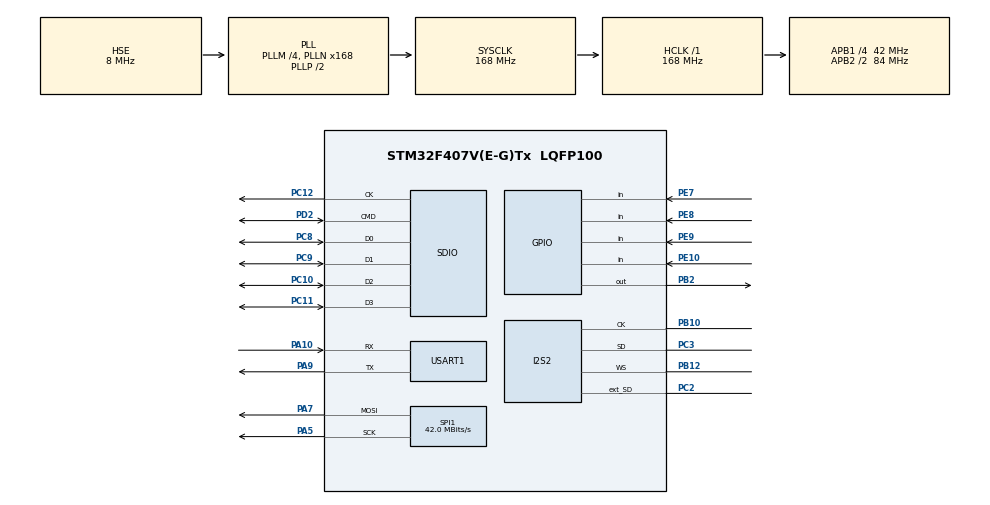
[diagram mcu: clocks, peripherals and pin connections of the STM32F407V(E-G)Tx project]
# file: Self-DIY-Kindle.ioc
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Dma.Request0=SDIO_RX
Dma.Request1=SDIO_TX
Dma.Request2=SPI1_TX
Dma.SDIO_RX.0.Direction=DMA_PERIPH_TO_MEMORY
Dma.SDIO_RX.0.FIFOMode=DMA_FIFOMODE_ENABLE
Dma.SDIO_RX.0.FIFOThreshold=DMA_FIFO_THRESHOLD_FULL
Dma.SDIO_RX.0.Instance=DMA2_Stream3
Dma.SDIO_RX.0.MemBurst=DMA_MBURST_INC4
Dma.SDIO_RX.0.MemDataAlignment=DMA_MDATAALIGN_WORD
Dma.SDIO_RX.0.MemInc=DMA_MINC_ENABLE
Dma.SDIO_RX.0.Mode=DMA_PFCTRL
Dma.SDIO_RX.0.PeriphBurst=DMA_PBURST_INC4
Dma.SDIO_RX.0.PeriphDataAlignment=DMA_PDATAALIGN_WORD
Dma.SDIO_RX.0.PeriphInc=DMA_PINC_DISABLE
Dma.SDIO_RX.0.Priority=DMA_PRIORITY_LOW
Dma.SDIO_TX.1.Direction=DMA_MEMORY_TO_PERIPH
Dma.SDIO_TX.1.FIFOMode=DMA_FIFOMODE_ENABLE
Dma.SDIO_TX.1.FIFOThreshold=DMA_FIFO_THRESHOLD_FULL
Dma.SDIO_TX.1.Instance=DMA2_Stream6
Dma.SDIO_TX.1.MemBurst=DMA_MBURST_INC4
Dma.SDIO_TX.1.MemDataAlignment=DMA_MDATAALIGN_WORD
Dma.SDIO_TX.1.MemInc=DMA_MINC_ENABLE
Dma.SDIO_TX.1.Mode=DMA_PFCTRL
Dma.SDIO_TX.1.PeriphBurst=DMA_PBURST_INC4
Dma.SDIO_TX.1.PeriphDataAlignment=DMA_PDATAALIGN_WORD
Dma.SDIO_TX.1.PeriphInc=DMA_PINC_DISABLE
Dma.SDIO_TX.1.Priority=DMA_PRIORITY_LOW
Dma.SPI1_TX.2.Direction=DMA_MEMORY_TO_PERIPH
Dma.SPI1_TX.2.FIFOMode=DMA_FIFOMODE_DISABLE
Dma.SPI1_TX.2.Instance=DMA2_Stream5
Dma.SPI1_TX.2.MemDataAlignment=DMA_MDATAALIGN_BYTE
Dma.SPI1_TX.2.MemInc=DMA_MINC_ENABLE
Dma.SPI1_TX.2.Mode=DMA_NORMAL
Dma.SPI1_TX.2.PeriphDataAlignment=DMA_PDATAALIGN_BYTE
Dma.SPI1_TX.2.PeriphInc=DMA_PINC_DISABLE
Dma.SPI1_TX.2.Priority=DMA_PRIORITY_LOW
FREERTOS.INCLUDE_vTaskDelayUntil=1
FREERTOS.Tasks01=defaultTask,-3,128,StartDefaultTask,Default,NULL,Dynamic,NULL,NULL;InputTask,1,128,StartInputTask,As external,NULL,Dynamic,NULL,NULL;MusicTask,0,128,StartMusicTask,As external,NULL,Dynamic,NULL,NULL;NetTask,-3,128,StartNetTask,As external,NULL,Dynamic,NULL,NULL;ProcessTask,-1,512,StartProcessTask,As external,NULL,Dynamic,NULL,NULL;UITask,0,1024,StartUITask,As external,NULL,Dynamic,NULL,NULL;TestTask,-3,512,StartTestTask,As external,NULL,Dynamic,NULL,NULL
FREERTOS.configCHECK_FOR_STACK_OVERFLOW=2
FREERTOS.configGENERATE_RUN_TIME_STATS=0
FREERTOS.configRECORD_STACK_HIGH_ADDRESS=1
I2S2.AudioFreq=I2S_AUDIOFREQ_96K
I2S2.DataFormat=I2S_DATAFORMAT_32B
I2S2.ErrorAudioFreq=0.8 %
I2S2.FullDuplexMode=I2S_FULLDUPLEXMODE_ENABLE
I2S2.Instance=SPI$Index
I2S2.RealAudioFreq=96.774 KHz
I2S2.VirtualMode=I2S_MODE_MASTER
Mcu.Family=STM32F4
Mcu.Name=STM32F407V(E-G)Tx
Mcu.Package=LQFP100
NVIC.DMA2_Stream3_IRQn=true\:5\:0\:false\:false\:true\:true\:false\:true\:true
NVIC.DMA2_Stream5_IRQn=true\:5\:0\:false\:false\:true\:true\:false\:true\:true
NVIC.DMA2_Stream6_IRQn=true\:5\:0\:false\:false\:true\:true\:false\:true\:true
NVIC.PriorityGroup=NVIC_PRIORITYGROUP_4
NVIC.TIM7_IRQn=true\:15\:0\:false\:false\:true\:false\:false\:true\:true
NVIC.TimeBase=TIM7_IRQn
NVIC.TimeBaseIP=TIM7
NVIC.USART1_IRQn=true\:5\:0\:false\:false\:true\:true\:true\:true\:true
PA10.Mode=Asynchronous
PA10.Signal=USART1_RX
PA13.Mode=Serial_Wire
PA13.Signal=SYS_JTMS-SWDIO
PA14.Mode=Serial_Wire
PA14.Signal=SYS_JTCK-SWCLK
PA5.Mode=TX_Only_Simplex_Unidirect_Master
PA5.Signal=SPI1_SCK
PA7.Mode=TX_Only_Simplex_Unidirect_Master
PA7.Signal=SPI1_MOSI
PA9.Mode=Asynchronous
PA9.Signal=USART1_TX
PB10.Mode=Full_Duplex_Master
PB10.Signal=I2S2_CK
PB12.Mode=Full_Duplex_Master
PB12.Signal=I2S2_WS
PB2.Signal=GPIO_Output
PC10.Mode=SD_4_bits_Wide_bus
PC10.Signal=SDIO_D2
PC11.Mode=SD_4_bits_Wide_bus
PC11.Signal=SDIO_D3
PC12.Mode=SD_4_bits_Wide_bus
PC12.Signal=SDIO_CK
PC14-OSC32_IN.Mode=LSE-External-Oscillator
PC14-OSC32_IN.Signal=RCC_OSC32_IN
PC15-OSC32_OUT.Mode=LSE-External-Oscillator
PC15-OSC32_OUT.Signal=RCC_OSC32_OUT
PC2.Mode=Full_Duplex_Master
PC2.Signal=I2S2_ext_SD
PC3.Mode=Full_Duplex_Master
PC3.Signal=I2S2_SD
PC8.Mode=SD_4_bits_Wide_bus
PC8.Signal=SDIO_D0
PC9.Mode=SD_4_bits_Wide_bus
PC9.Signal=SDIO_D1
PD2.Mode=SD_4_bits_Wide_bus
PD2.Signal=SDIO_CMD
PE10.Signal=GPIO_Input
PE7.Signal=GPIO_Input
PE8.Signal=GPIO_Input
PE9.Signal=GPIO_Input
PH0-OSC_IN.Mode=HSE-External-Oscillator
PH0-OSC_IN.Signal=RCC_OSC_IN
PH1-OSC_OUT.Mode=HSE-External-Oscillator
PH1-OSC_OUT.Signal=RCC_OSC_OUT
ProjectManager.HeapSize=0x200
ProjectManager.StackSize=0x400
ProjectManager.TargetToolchain=Makefile
RCC.48MHZClocksFreq_Value=42000000
RCC.AHBFreq_Value=168000000
RCC.APB1CLKDivider=RCC_HCLK_DIV4
RCC.APB1Freq_Value=42000000
RCC.APB1TimFreq_Value=84000000
RCC.APB2CLKDivider=RCC_HCLK_DIV2
RCC.APB2Freq_Value=84000000
RCC.APB2TimFreq_Value=168000000
RCC.CortexFreq_Value=168000000
RCC.HCLKFreq_Value=168000000
RCC.HSE_VALUE=8000000
RCC.HSI_VALUE=16000000
RCC.PLLM=4
RCC.PLLN=168
RCC.PLLQ=8
RCC.PLLSourceVirtual=RCC_PLLSOURCE_HSE
RCC.SYSCLKFreq_VALUE=168000000
RCC.SYSCLKSource=RCC_SYSCLKSOURCE_PLLCLK
RCC.VCOOutputFreq_Value=336000000
SPI1.CalculateBaudRate=42.0 MBits/s
SPI1.Direction=SPI_DIRECTION_2LINES
SPI1.Mode=SPI_MODE_MASTER
SPI1.VirtualType=VM_MASTER
USART1.VirtualMode=VM_ASYNC
VP_FREERTOS_VS_CMSIS_V1.Mode=CMSIS_V1
VP_SYS_VS_tim7.Mode=TIM7
board=custom

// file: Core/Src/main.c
/* USER CODE BEGIN Header */
/**
 ******************************************************************************
 * @file           : main.c
 * @brief          : Main program body
 ******************************************************************************
 * @attention
 *
 * Copyright (c) 2026 STMicroelectronics.
 * All rights reserved.
 *
 * This software is licensed under terms that can be found in the LICENSE file
 * in the root directory of this software component.
 * If no LICENSE file comes with this software, it is provided AS-IS.
 *
 ******************************************************************************
 */
/* USER CODE END Header */
#include "main.h"
#include "cmsis_os.h"
#include "dma.h"
#include "i2s.h"
#include "sdio.h"
#include "spi.h"
#include "usart.h"
#include "gpio.h"

/* USER CODE BEGIN Includes */
#include "bsp_config.h"
#include "bsp_sys.h"
#include "mid_config.h"
#include "srv_config.h"

/* USER CODE END Includes */

void SystemClock_Config(void);
void MX_FREERTOS_Init(void);

int main(void)
{

  /* MCU Configuration--------------------------------------------------------*/

  /* Reset of all peripherals, Initializes the Flash interface and the Systick. */
  HAL_Init();

  /* Configure the system clock */
  SystemClock_Config();

  /* Initialize all configured peripherals */
  MX_GPIO_Init();
  MX_DMA_Init();
  MX_SDIO_SD_Init();
  MX_SPI1_Init();
  MX_USART1_UART_Init();
  MX_I2S2_Init();
  /* USER CODE BEGIN 2 */
    /* 初始化 RTT 调试支持 */
    rtt_init();
    sys_chip_init();
    bsp_init_hardware();
    mid_init_modules();

    service_init();

    /* start testing signal */
    gpio_write(&usr_led, GPIO_Level_High);
  /* USER CODE END 2 */

  /* Call init function for freertos objects (in cmsis_os2.c) */
  MX_FREERTOS_Init();

  /* Start scheduler */
  osKernelStart();

  /* We should never get here as control is now taken by the scheduler */

  /* Infinite loop */
    while (1) {

    }
}

void SystemClock_Config(void)
{
  RCC_OscInitTypeDef RCC_OscInitStruct = {0};
  RCC_ClkInitTypeDef RCC_ClkInitStruct = {0};

  /** Configure the main internal regulator output voltage
  */
  __HAL_RCC_PWR_CLK_ENABLE();
  __HAL_PWR_VOLTAGESCALING_CONFIG(PWR_REGULATOR_VOLTAGE_SCALE1);

  /** Initializes the RCC Oscillators according to the specified parameters
  * in the RCC_OscInitTypeDef structure.
  */
  RCC_OscInitStruct.OscillatorType = RCC_OSCILLATORTYPE_HSE;
  RCC_OscInitStruct.HSEState = RCC_HSE_ON;
  RCC_OscInitStruct.PLL.PLLState = RCC_PLL_ON;
  RCC_OscInitStruct.PLL.PLLSource = RCC_PLLSOURCE_HSE;
  RCC_OscInitStruct.PLL.PLLM = 4;
  RCC_OscInitStruct.PLL.PLLN = 168;
  RCC_OscInitStruct.PLL.PLLP = RCC_PLLP_DIV2;
  RCC_OscInitStruct.PLL.PLLQ = 8;
  if (HAL_RCC_OscConfig(&RCC_OscInitStruct) != HAL_OK)
  {
    Error_Handler();
  }

  /** Initializes the CPU, AHB and APB buses clocks
  */
  RCC_ClkInitStruct.ClockType = RCC_CLOCKTYPE_HCLK|RCC_CLOCKTYPE_SYSCLK
                              |RCC_CLOCKTYPE_PCLK1|RCC_CLOCKTYPE_PCLK2;
  RCC_ClkInitStruct.SYSCLKSource = RCC_SYSCLKSOURCE_PLLCLK;
  RCC_ClkInitStruct.AHBCLKDivider = RCC_SYSCLK_DIV1;
  RCC_ClkInitStruct.APB1CLKDivider = RCC_HCLK_DIV4;
  RCC_ClkInitStruct.APB2CLKDivider = RCC_HCLK_DIV2;

  if (HAL_RCC_ClockConfig(&RCC_ClkInitStruct, FLASH_LATENCY_5) != HAL_OK)
  {
    Error_Handler();
  }
}

void HAL_TIM_PeriodElapsedCallback(TIM_HandleTypeDef *htim)
{
  if (htim->Instance == TIM7)
  {
    HAL_IncTick();
  }
}

void Error_Handler(void)
{
  /* USER CODE BEGIN Error_Handler_Debug */
    /* User can add his own implementation to report the HAL error return state */
    __disable_irq();
    gpio_write(&usr_led, GPIO_Level_Low);
    while (1) {
    }
  /* USER CODE END Error_Handler_Debug */
}

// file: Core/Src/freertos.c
/* USER CODE BEGIN Header */
/**
  ******************************************************************************
  * File Name          : freertos.c
  * Description        : Code for freertos applications
  ******************************************************************************
  * @attention
  *
  * Copyright (c) 2026 STMicroelectronics.
  * All rights reserved.
  *
  * This software is licensed under terms that can be found in the LICENSE file
  * in the root directory of this software component.
  * If no LICENSE file comes with this software, it is provided AS-IS.
  *
  ******************************************************************************
  */
/* USER CODE END Header */

#include "FreeRTOS.h"
#include "task.h"
#include "main.h"
#include "cmsis_os.h"

osThreadId defaultTaskHandle;
osThreadId InputTaskHandle;
osThreadId MusicTaskHandle;
osThreadId NetTaskHandle;
osThreadId ProcessTaskHandle;
osThreadId UITaskHandle;
osThreadId TestTaskHandle;

void StartDefaultTask(void const * argument);
extern void StartInputTask(void const * argument);
extern void StartMusicTask(void const * argument);
extern void StartNetTask(void const * argument);
extern void StartProcessTask(void const * argument);
extern void StartUITask(void const * argument);
extern void StartTestTask(void const * argument);

void MX_FREERTOS_Init(void); /* (MISRA C 2004 rule 8.1) */

/* GetIdleTaskMemory prototype (linked to static allocation support) */
void vApplicationGetIdleTaskMemory( StaticTask_t **ppxIdleTaskTCBBuffer, StackType_t **ppxIdleTaskStackBuffer, uint32_t *pulIdleTaskStackSize );

/* Hook prototypes */
void vApplicationStackOverflowHook(xTaskHandle xTask, signed char *pcTaskName);

/* USER CODE BEGIN 4 */
__weak void vApplicationStackOverflowHook(xTaskHandle xTask, signed char *pcTaskName)
{
   /* Run time stack overflow checking is performed if
   configCHECK_FOR_STACK_OVERFLOW is defined to 1 or 2. This hook function is
   called if a stack overflow is detected. */
}
/* USER CODE END 4 */

/* USER CODE BEGIN GET_IDLE_TASK_MEMORY */
static StaticTask_t xIdleTaskTCBBuffer;
static StackType_t xIdleStack[configMINIMAL_STACK_SIZE];

void vApplicationGetIdleTaskMemory( StaticTask_t **ppxIdleTaskTCBBuffer, StackType_t **ppxIdleTaskStackBuffer, uint32_t *pulIdleTaskStackSize )
{
  *ppxIdleTaskTCBBuffer = &xIdleTaskTCBBuffer;
  *ppxIdleTaskStackBuffer = &xIdleStack[0];
  *pulIdleTaskStackSize = configMINIMAL_STACK_SIZE;
  /* place for user code */
}
/* USER CODE END GET_IDLE_TASK_MEMORY */

void MX_FREERTOS_Init(void) {

  /* Create the thread(s) */
  /* definition and creation of defaultTask */
  osThreadDef(defaultTask, StartDefaultTask, osPriorityIdle, 0, 128);
  defaultTaskHandle = osThreadCreate(osThread(defaultTask), NULL);

  /* definition and creation of InputTask */
  osThreadDef(InputTask, StartInputTask, osPriorityAboveNormal, 0, 128);
  InputTaskHandle = osThreadCreate(osThread(InputTask), NULL);

  /* definition and creation of MusicTask */
  osThreadDef(MusicTask, StartMusicTask, osPriorityNormal, 0, 128);
  MusicTaskHandle = osThreadCreate(osThread(MusicTask), NULL);

  /* definition and creation of NetTask */
  osThreadDef(NetTask, StartNetTask, osPriorityIdle, 0, 128);
  NetTaskHandle = osThreadCreate(osThread(NetTask), NULL);

  /* definition and creation of ProcessTask */
  osThreadDef(ProcessTask, StartProcessTask, osPriorityBelowNormal, 0, 512);
  ProcessTaskHandle = osThreadCreate(osThread(ProcessTask), NULL);

  /* definition and creation of UITask */
  osThreadDef(UITask, StartUITask, osPriorityNormal, 0, 1024);
  UITaskHandle = osThreadCreate(osThread(UITask), NULL);

  /* definition and creation of TestTask */
  osThreadDef(TestTask, StartTestTask, osPriorityIdle, 0, 512);
  TestTaskHandle = osThreadCreate(osThread(TestTask), NULL);

}

void StartDefaultTask(void const * argument)
{
  for(;;)
  {
    osDelay(1);
  }
}
